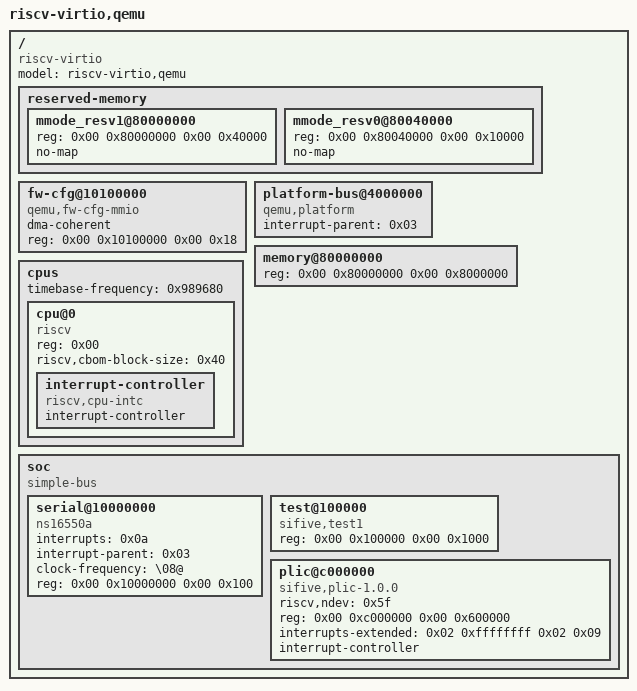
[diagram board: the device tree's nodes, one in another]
// Copyright 2023 Andrew Oates.  All Rights Reserved.
//
// Licensed under the Apache License, Version 2.0 (the "License");
// you may not use this file except in compliance with the License.
// You may obtain a copy of the License at
//
//     http://www.apache.org/licenses/LICENSE-2.0
//
// Unless required by applicable law or agreed to in writing, software
// distributed under the License is distributed on an "AS IS" BASIS,
// WITHOUT WARRANTIES OR CONDITIONS OF ANY KIND, either express or implied.
// See the License for the specific language governing permissions and
// limitations under the License.

/dts-v1/;

/ {
	#address-cells = <0x02>;
	#size-cells = <0x02>;
	compatible = "riscv-virtio";
	model = "riscv-virtio,qemu";

	reserved-memory {
		#address-cells = <0x02>;
		#size-cells = <0x02>;
		ranges;

		mmode_resv1@80000000 {
			reg = <0x00 0x80000000 0x00 0x40000>;
			no-map;
		};

		mmode_resv0@80040000 {
			reg = <0x00 0x80040000 0x00 0x10000>;
			no-map;
		};
	};

	fw-cfg@10100000 {
		dma-coherent;
		reg = <0x00 0x10100000 0x00 0x18>;
		compatible = "qemu,fw-cfg-mmio";
	};

	platform-bus@4000000 {
		interrupt-parent = <0x03>;
		ranges = <0x00 0x00 0x4000000 0x2000000>;
		#address-cells = <0x01>;
		#size-cells = <0x01>;
		compatible = "qemu,platform\0simple-bus";
	};

	memory@80000000 {
		device_type = "memory";
		reg = <0x00 0x80000000 0x00 0x8000000>;
	};

	cpus {
		#address-cells = <0x01>;
		#size-cells = <0x00>;
		timebase-frequency = <0x989680>;

		cpu@0 {
			phandle = <0x01>;
			reg = <0x00>;
			compatible = "riscv";
			riscv,cbom-block-size = <0x40>;

			interrupt-controller {
				#interrupt-cells = <0x01>;
				interrupt-controller;
				compatible = "riscv,cpu-intc";
				phandle = <0x02>;
			};
		};
	};

	soc {
		#address-cells = <0x02>;
		#size-cells = <0x02>;
		compatible = "simple-bus";
		ranges;

		serial@10000000 {
			interrupts = <0x0a>;
			interrupt-parent = <0x03>;
			clock-frequency = "\08@";
			reg = <0x00 0x10000000 0x00 0x100>;
			compatible = "ns16550a";
		};

		test@100000 {
			phandle = <0x04>;
			reg = <0x00 0x100000 0x00 0x1000>;
			compatible = "sifive,test1\0sifive,test0\0syscon";
		};

		plic@c000000 {
			phandle = <0x03>;
			riscv,ndev = <0x5f>;
			reg = <0x00 0xc000000 0x00 0x600000>;
			interrupts-extended = <0x02 0xffffffff 0x02 0x09>;
			interrupt-controller;
			compatible = "sifive,plic-1.0.0\0riscv,plic0";
			#address-cells = <0x00>;
			#interrupt-cells = <0x01>;
		};
	};
};
